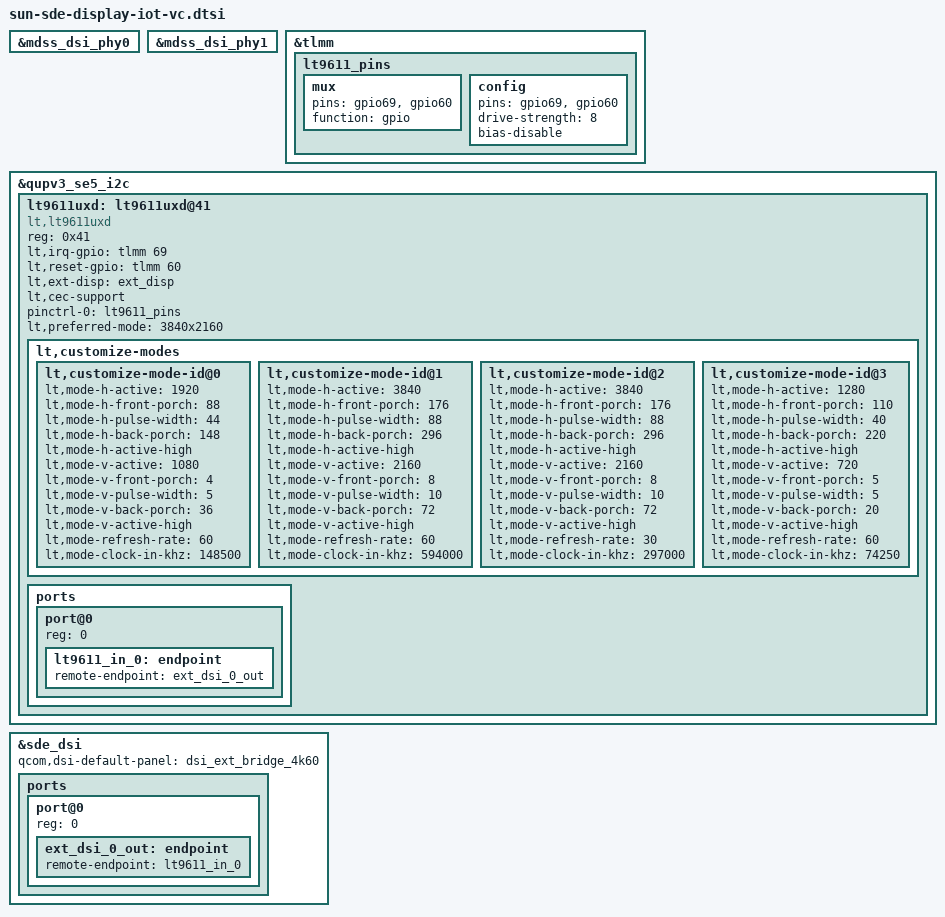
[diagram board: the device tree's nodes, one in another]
// SPDX-License-Identifier: BSD-3-Clause
/*
 * Copyright (c) Qualcomm Technologies, Inc. and/or its subsidiaries.
 */

#include "sun-sde-display.dtsi"

&mdss_dsi_phy0 {
	/delete-property/ qcom,dsi-pll-ssc-en;
};

&mdss_dsi_phy1 {
	/delete-property/ qcom,dsi-pll-ssc-en;
};

&tlmm {
	lt9611_pins: lt9611_pins {
		mux {
			pins = "gpio69", "gpio60";
			function = "gpio";
		};

		config {
			pins = "gpio69", "gpio60";
			drive-strength = <8>;
			bias-disable;
		};
	};
};

&qupv3_se5_i2c {
	status = "ok";

	lt9611uxd: lt9611uxd@41 {
		compatible = "lt,lt9611uxd";
		reg = <0x41>;
		lt,irq-gpio = <&tlmm 69 0x0>;
		lt,reset-gpio = <&tlmm 60 0x0>;
		lt,ext-disp = <&ext_disp>;
		lt,cec-support;
		pinctrl-names = "default";
		pinctrl-0 = <&lt9611_pins>;
		lt,preferred-mode = "3840x2160";
		lt,customize-modes {
			lt,customize-mode-id@0 {
				lt,mode-h-active = <1920>;
				lt,mode-h-front-porch = <88>;
				lt,mode-h-pulse-width = <44>;
				lt,mode-h-back-porch = <148>;
				lt,mode-h-active-high;
				lt,mode-v-active = <1080>;
				lt,mode-v-front-porch = <4>;
				lt,mode-v-pulse-width = <5>;
				lt,mode-v-back-porch = <36>;
				lt,mode-v-active-high;
				lt,mode-refresh-rate = <60>;
				lt,mode-clock-in-khz = <148500>;
			};

			lt,customize-mode-id@1 {
				lt,mode-h-active = <3840>;
				lt,mode-h-front-porch = <176>;
				lt,mode-h-pulse-width = <88>;
				lt,mode-h-back-porch = <296>;
				lt,mode-h-active-high;
				lt,mode-v-active = <2160>;
				lt,mode-v-front-porch = <8>;
				lt,mode-v-pulse-width = <10>;
				lt,mode-v-back-porch = <72>;
				lt,mode-v-active-high;
				lt,mode-refresh-rate = <60>;
				lt,mode-clock-in-khz = <594000>;
			};

			lt,customize-mode-id@2 {
				lt,mode-h-active = <3840>;
				lt,mode-h-front-porch = <176>;
				lt,mode-h-pulse-width = <88>;
				lt,mode-h-back-porch = <296>;
				lt,mode-h-active-high;
				lt,mode-v-active = <2160>;
				lt,mode-v-front-porch = <8>;
				lt,mode-v-pulse-width = <10>;
				lt,mode-v-back-porch = <72>;
				lt,mode-v-active-high;
				lt,mode-refresh-rate = <30>;
				lt,mode-clock-in-khz = <297000>;
			};

			lt,customize-mode-id@3 {
				lt,mode-h-active = <1280>;
				lt,mode-h-front-porch = <110>;
				lt,mode-h-pulse-width = <40>;
				lt,mode-h-back-porch = <220>;
				lt,mode-h-active-high;
				lt,mode-v-active = <720>;
				lt,mode-v-front-porch = <5>;
				lt,mode-v-pulse-width = <5>;
				lt,mode-v-back-porch = <20>;
				lt,mode-v-active-high;
				lt,mode-refresh-rate = <60>;
				lt,mode-clock-in-khz = <74250>;
			};
		};

		ports {
			#address-cells = <1>;
			#size-cells = <0>;
			port@0 {
				reg = <0>;
				lt9611_in_0: endpoint {
					remote-endpoint = <&ext_dsi_0_out>;
				};
			};
		};
	};
};

&sde_dsi {
	qcom,dsi-default-panel = <&dsi_ext_bridge_4k60>;
	ports {
		#address-cells = <1>;
		#size-cells = <0>;

		port@0 {
			reg = <0>;
			ext_dsi_0_out: endpoint {
				remote-endpoint = <&lt9611_in_0>;
			};
		};
	};
};
